# GD32W515 register map
File version: 1.0
CPU: CM33 r0p4, little endian, MPU, FPU, 4 interrupt priority bits
Registers are 32-bit, read-write, reset 0x0 unless marked. A register's access mark holds for its fields unless they carry their own. Offsets are from the block's base; [hi:lo] are bit positions; {n}, {i} and the like mark numbered series; 'fields as' and 'values as' point back to an identical list.

## FS_HOST — USB on the go full speed host
Base 0x49000400
Same registers: SEC_FS_HOST 0x59000400
0x00 HCTL — host configuration register (HCTL)
  [1:0] CLKSEL — clock select for USB clock
0x04 HFT reset 0xBB80 — Host frame interval register
  [15:0] FRI — Frame interval
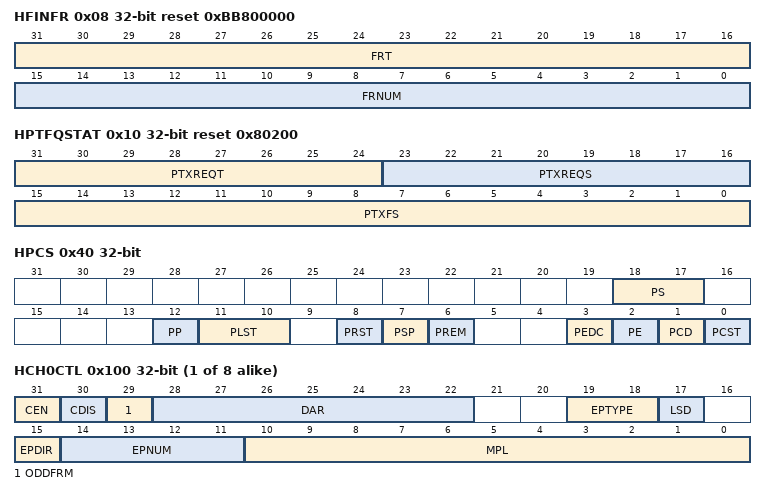
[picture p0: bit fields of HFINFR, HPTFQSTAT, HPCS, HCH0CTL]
0x08 HFINFR ro reset 0xBB800000 — OTG_FS host frame number/frame time remaining register (HFINFR)
  [31:16] FRT — Frame remaining time
  [15:0] FRNUM — Frame number
0x10 HPTFQSTAT ro reset 0x80200 — Host periodic transmit FIFO/queue status register (HPTFQSTAT)
  [31:24] PTXREQT — Top of the periodic transmit request queue
  [23:16] PTXREQS — Periodic transmit request queue space available
  [15:0] PTXFS — Periodic transmit data FIFO space available
0x14 HACHINT ro — Host all channels interrupt register
  [7:0] HACHINT — Host all channel interrupts
0x18 HACHINTEN — host all channels interrupt mask register
  [7:0] CINTEN — Channel interrupt enable
0x40 HPCS access per field — Host port control and status register (USBFS_HPCS)
  [18:17] PS ro — Port speed
  [12] PP rw — Port power
  [11:10] PLST ro — Port line status
  [8] PRST rw — Port reset
  [7] PSP rw — Port suspend
  [6] PREM rw — Port resume
  [3] PEDC rw — Port enable/disable change
  [2] PE rw — Port enable
  [1] PCD rw — Port connect detected
  [0] PCST ro — Port connect status
{0x100+0x20*i} HCH{i}CTL (i=0..7) — host channel-{i} characteristics register (HCH{i}CTL)
  [31] CEN — Channel enable
  [30] CDIS — Channel disable
  [29] ODDFRM — Odd frame
  [28:22] DAR — Device address
  [19:18] EPTYPE — Endpoint type
  [17] LSD — Low-speed device
  [15] EPDIR — Endpoint direction
  [14:11] EPNUM — Endpoint number
  [10:0] MPL — Maximum packet size
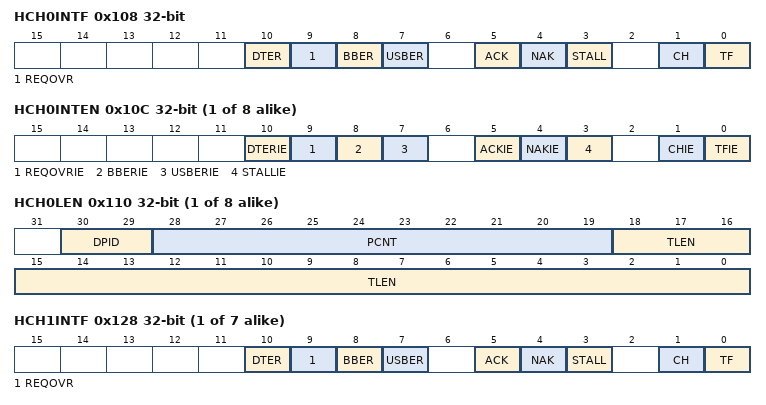
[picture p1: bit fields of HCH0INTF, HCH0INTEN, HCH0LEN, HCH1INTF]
0x108 HCH0INTF — host channel-0 interrupt register (USBFS_HCHxINTF)
  [10] DTER — Data toggle error
  [9] REQOVR — Request queue overrun
  [8] BBER — Babble error
  [7] USBER — USB bus error
  [5] ACK — ACK response received/transmitted interrupt
  [4] NAK — NAK response received interrupt
  [3] STALL — STALL response received interrupt
  [1] CH — Channel halted
  [0] TF — Transfer finished
{0x10C+0x20*i} HCH{i}INTEN (i=0..7) — host channel-{i} interrupt enable register (HCH{i}INTEN)
  [10] DTERIE — Data toggle error interrupt enable
  [9] REQOVRIE — request queue overrun interrupt enable
  [8] BBERIE — Babble error interrupt enable
  [7] USBERIE — USB bus error interrupt enable
  [5] ACKIE — ACK interrupt enable
  [4] NAKIE — NAK interrupt enable
  [3] STALLIE — STALL interrupt enable
  [1] CHIE — Channel halted interrupt enable
  [0] TFIE — Transfer completed interrupt enable
{0x110+0x20*i} HCH{i}LEN (i=0..7) — host channel-{i} transfer length register
  [30:29] DPID — Data PID
  [28:19] PCNT — Packet count
  [18:0] TLEN — Transfer length
{0x108+0x20*i} HCH{i}INTF (i=1..7) — host channel-{i} interrupt register (HCH{i}INTF)
  fields as HCH0INTF

## FS_PWRCLK — USB on the go full speed
Base 0x49000E00
Same registers: SEC_FS_PWRCLK 0x59000E00
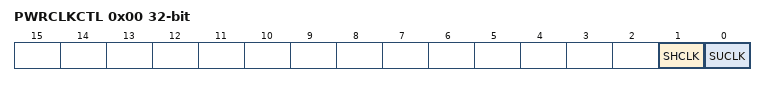
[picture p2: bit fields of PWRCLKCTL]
0x00 PWRCLKCTL — power and clock gating control register (PWRCLKCTL)
  [1] SHCLK — Stop HCLK
  [0] SUCLK — Stop the USB clock

## FWDGT — free watchdog timer
Base 0x40003000
Same registers: SEC_FWDGT 0x50003000
0x00 CTL wo — Control register
  [15:0] CMD — Key value
0x04 PSC — Prescaler register
  [2:0] PSC — Prescaler divider
0x08 RLD reset 0xFFF — Reload register
  [11:0] RLD — Free watchdog timer counter reload value
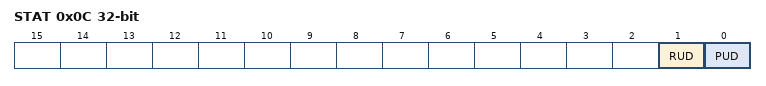
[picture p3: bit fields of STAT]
0x0C STAT ro — Status register
  [1] RUD — Free watchdog timer counter reload value update
  [0] PUD — Free watchdog timer prescaler value update

## GPIOA — General-purpose I/Os
Base 0x40020000
Same registers: SEC_GPIOA 0x50020000
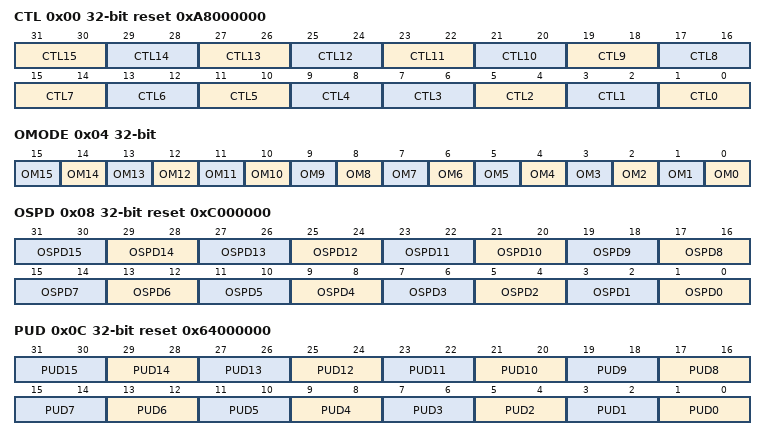
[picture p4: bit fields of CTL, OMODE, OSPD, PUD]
0x00 CTL reset 0xA8000000 — GPIO port control register
  [2n+1:2n] CTL{n} (n=7..15) — Port x configuration bits (x = {n})
  [13:12] CTL6 — Port x configuration bits (x = 6 )
  [11:10] CTL5 — Port x configuration bits (x = 5)
  [9:8] CTL4 — Port x configuration bits (x = 4 )
  [2n+1:2n] CTL{n} (n=0..3) — Port x configuration bits (x = {n})
0x04 OMODE — GPIO port output mode register
  [n] OM{n} (n=0..15) — Port {n} output mode bit
0x08 OSPD reset 0xC000000 — GPIO port output speed register
  [2n+1:2n] OSPD{n} (n=0..15) — Port {n} output max speed bits
0x0C PUD reset 0x64000000 — GPIO port pull-up/pull-down register
  [2n+1:2n] PUD{n} (n=0..15) — Port {n} pull-up or pull-down bits
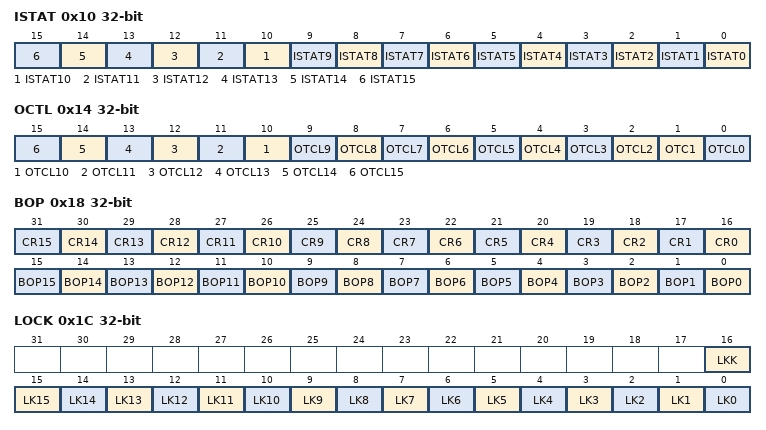
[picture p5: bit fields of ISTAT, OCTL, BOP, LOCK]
0x10 ISTAT ro — GPIO port input status register
  [n] ISTAT{n} (n=0..15) — Port input status (y = {n})
0x14 OCTL — Port output control register
  [n] OTCL{n} (n=2..15) — Pin output control(y=0..15)
  [1] OTC1 — Pin output control(y=0..15)
  [0] OTCL0 — Pin output control(y=0..15)
0x18 BOP wo — GPIO port bit operate register
  [n+16] CR{n} (n=0..15) — Port Clear bit {n}
  [n] BOP{n} (n=0..15) — Port Set bit {n}
0x1C LOCK — GPIO port configuration lock register
  [16] LKK — Lock sequence key
  [n] LK{n} (n=0..15) — Port Lock bit {n}
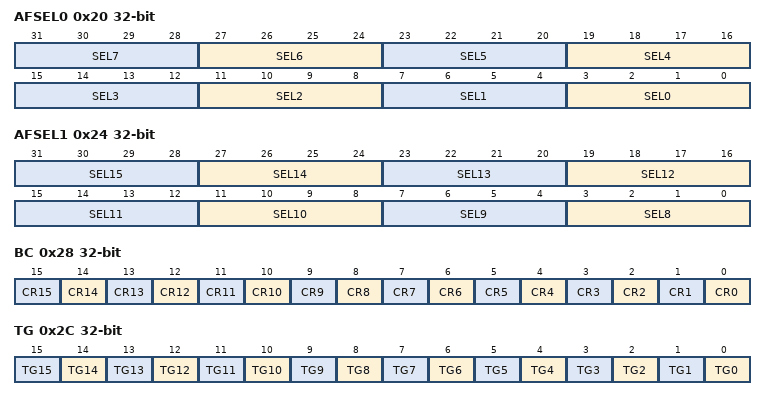
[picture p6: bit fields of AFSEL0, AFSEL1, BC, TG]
0x20 AFSEL0 — GPIO alternate function selected register 0
  [4n+3:4n] SEL{n} (n=0..7) — Port {n} alternate function selected
0x24 AFSEL1 — GPIO alternate function selected register 1
  [4n-29:4n-32] SEL{n} (n=8..15) — Port {n} alternate function selected
0x28 BC wo — Bit clear register
  [n] CR{n} (n=0..15) — Port cleat bit
0x2C TG wo — Port bit toggle register
  [n] TG{n} (n=0..15) — Port toggle bit
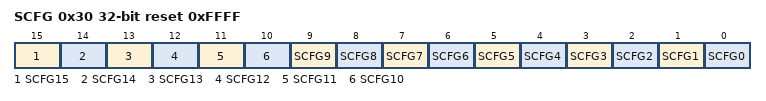
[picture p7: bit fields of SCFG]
0x30 SCFG reset 0xFFFF — GPIO secure configuration register
  [15] SCFG15 — Port A secure bit configure y (y= 15)
  [14] SCFG14 — Port A secure bit configure y (y= 14)
  [13] SCFG13 — Port A secure bit configure y (y= 13)
  [12] SCFG12 — Port A secure bit configure y (y= 12)
  [11] SCFG11 — Port A secure bit configure y (y= 11)
  [10] SCFG10 — Port A secure bit configure y (y= 10)
  [9] SCFG9 — Port A secure bit configure y (y= 9)
  [8] SCFG8 — Port A secure bit configure y (y= 8)
  [7] SCFG7 — Port A secure bit configure y (y= 7)
  [6] SCFG6 — Port A secure bit configure y (y= 6)
  [5] SCFG5 — Port A secure bit configure y (y= 5)
  [4] SCFG4 — Port A secure bit configure y (y= 4)
  [3] SCFG3 — Port A secure bit configure y (y= 3)
  [2] SCFG2 — Port A secure bit configure y (y= 2)
  [1] SCFG1 — Port A secure bit configure y (y= 1)
  [0] SCFG0 — Port A secure bit configure y (y= 0)

## GPIOB — General-purpose I/Os
Base 0x40020400
Same registers: SEC_GPIOB 0x50020400
Registers as GPIOA; these are added or differ:
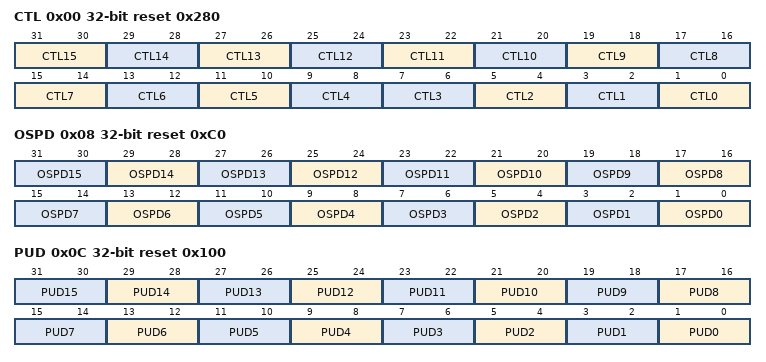
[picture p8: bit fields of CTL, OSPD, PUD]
0x00 CTL reset 0x280 — GPIO port control register
  fields as GPIOA.CTL
0x08 OSPD reset 0xC0 — GPIO port output speed register
  [2n+1:2n] OSPD{n} (n=0..15) — Port {n} output max speed bits
0x0C PUD reset 0x100 — GPIO port pull-up/pull-down register
  [2n+1:2n] PUD{n} (n=0..15) — Port {n} pull-up or pull-down bits

## GPIOC — General-purpose I/Os
Base 0x40020800
Same registers: SEC_GPIOC 0x50020800
Registers as GPIOA; these are added or differ:
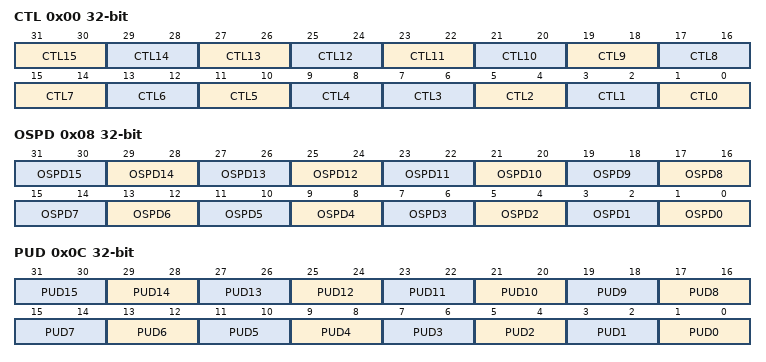
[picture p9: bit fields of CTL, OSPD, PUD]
0x00 CTL — GPIO port control register
  fields as GPIOA.CTL
0x08 OSPD — GPIO port output speed register
  [2n+1:2n] OSPD{n} (n=0..15) — Port {n} output max speed bits
0x0C PUD — GPIO port pull-up/pull-down register
  [2n+1:2n] PUD{n} (n=0..15) — Port {n} pull-up or pull-down bits
